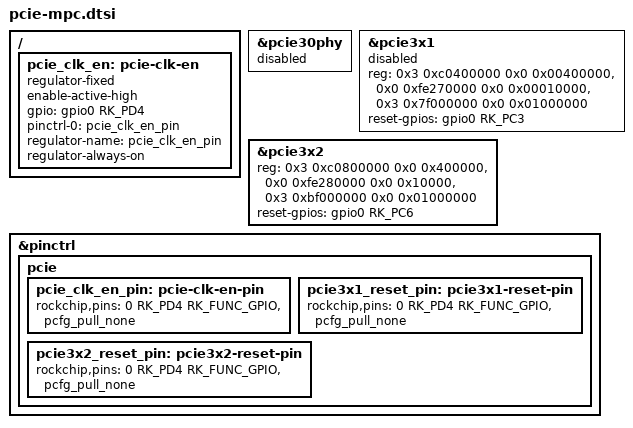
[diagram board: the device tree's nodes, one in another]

/{
/*
    This is dummy regulator.
    It is used to have ability to activate PCIE clocks
*/
    pcie_clk_en: pcie-clk-en {
        compatible = "regulator-fixed";
        enable-active-high;
        // 1V8_PCIE_PWREN
        gpio = <&gpio0 RK_PD4 GPIO_ACTIVE_HIGH>;
        pinctrl-names = "default";
        pinctrl-0 = <&pcie_clk_en_pin>;
        regulator-name = "pcie_clk_en_pin";
        regulator-always-on;
    };
/*
    1V8_PCIE_PWREN -> VT14(NMOS)->PCIe_EN_ -> VT15 (PMOS) -> +3.3v2_M2_CON
    0 -> 1 -> 0
    1 -> 0 -> 1

    +3.3v2_M2_CON supplies device connected to X18 (m.2 B/M)

    1V8_PCIE_PWREN -> VT14(NMOS)->PCIe_EN_ -> VT28 (PMOS) -> +3.3vPCIe
    0 -> 1 -> 0
    1 -> 0 -> 1

    +3.3vPCIe supplies D8 (SFP) and activtes generating PCIE30_REFCLKP/PCIE30_REFCLKN (reference clocks for PCIE3x controller) clocks

    D14 multiplexor is responsible for switching PCIE30_TX1P/PCIE30_TX1N and PCIE30_RX1P/PCIE30_RX1N between X18 and D8(SFP)
*/	
};

&pcie30phy {
	status = "disabled";
};

&pcie3x1 {
    reg = <0x3 0xc0400000 0x0 0x00400000>,
            <0x0 0xfe270000 0x0 0x00010000>,
            <0x3 0x7f000000 0x0 0x01000000>;

    ranges = <0x00000800 0x0 0xf2000000 0x0 0xf2000000 0x0 0x100000>,
            <0x81000000 0x0 0xf2100000 0x0 0xf2100000 0x0 0x100000>,
            <0x82000000 0x0 0xf2200000 0x0 0xf2200000 0x0 0x1e00000>,
            <0xc3000000 0x3 0x40000000 0x3 0x40000000 0x0 0x3ef00000>;
/*
    PCIE30X1_PERSTn -> R115(0) -> D8
    0 -> 0
    1 -> 1
*/    
    reset-gpios = <&gpio0 RK_PC3 GPIO_ACTIVE_HIGH>;

    status = "disabled";
};

&pcie3x2 {

	reg = <0x3 0xc0800000 0x0 0x400000>,
	      <0x0 0xfe280000 0x0 0x10000>,
		  <0x3 0xbf000000 0x0 0x01000000>;

	ranges = <0x00000800 0x0 0xf0000000 0x0 0xf0000000 0x0 0x100000>,
		  <0x81000000 0x0 0xf0100000 0x0 0xf0100000 0x0 0x100000>,
		  <0x82000000 0x0 0xf0200000 0x0 0xf0200000 0x0 0x1e00000>,
		  <0xc3000000 0x3 0x80000000 0x3 0x80000000 0x0 0x3ef00000>;

/*
    PCIE30X2_PERSTn is pulled up to +3.3vPCIe via R116(10K)
    PCIE30X2_PERSTn -> R179(0) -> M2_PCIE_RSTn (X18 m.2 B/M PERST#)
    0 -> 0
    1 -> 1
*/
    reset-gpios = <&gpio0 RK_PC6 GPIO_ACTIVE_HIGH>;

    status = "okay";
};


&pinctrl {
	pcie {
		pcie_clk_en_pin: pcie-clk-en-pin {
			// 1V8_PCIE_PWREN
			rockchip,pins = <0 RK_PD4 RK_FUNC_GPIO &pcfg_pull_none>;
		};

		pcie3x1_reset_pin: pcie3x1-reset-pin {
/*
            PCIE30X1_PERSTn -> R115(0) -> D8
            0 -> 0
            1 -> 1
*/
            rockchip,pins = <0 RK_PD4 RK_FUNC_GPIO &pcfg_pull_none>;
		};
	
        pcie3x2_reset_pin: pcie3x2-reset-pin {
/*
            PCIE30X2_PERSTn is pulled up to +3.3vPCIe via R116(10K)
            PCIE30X2_PERSTn -> R179(0) -> M2_PCIE_RSTn (X18 m.2 B/M PERST#)
            0 -> 0
            1 -> 1
*/
            rockchip,pins = <0 RK_PD4 RK_FUNC_GPIO &pcfg_pull_none>;
		};
	};
};
